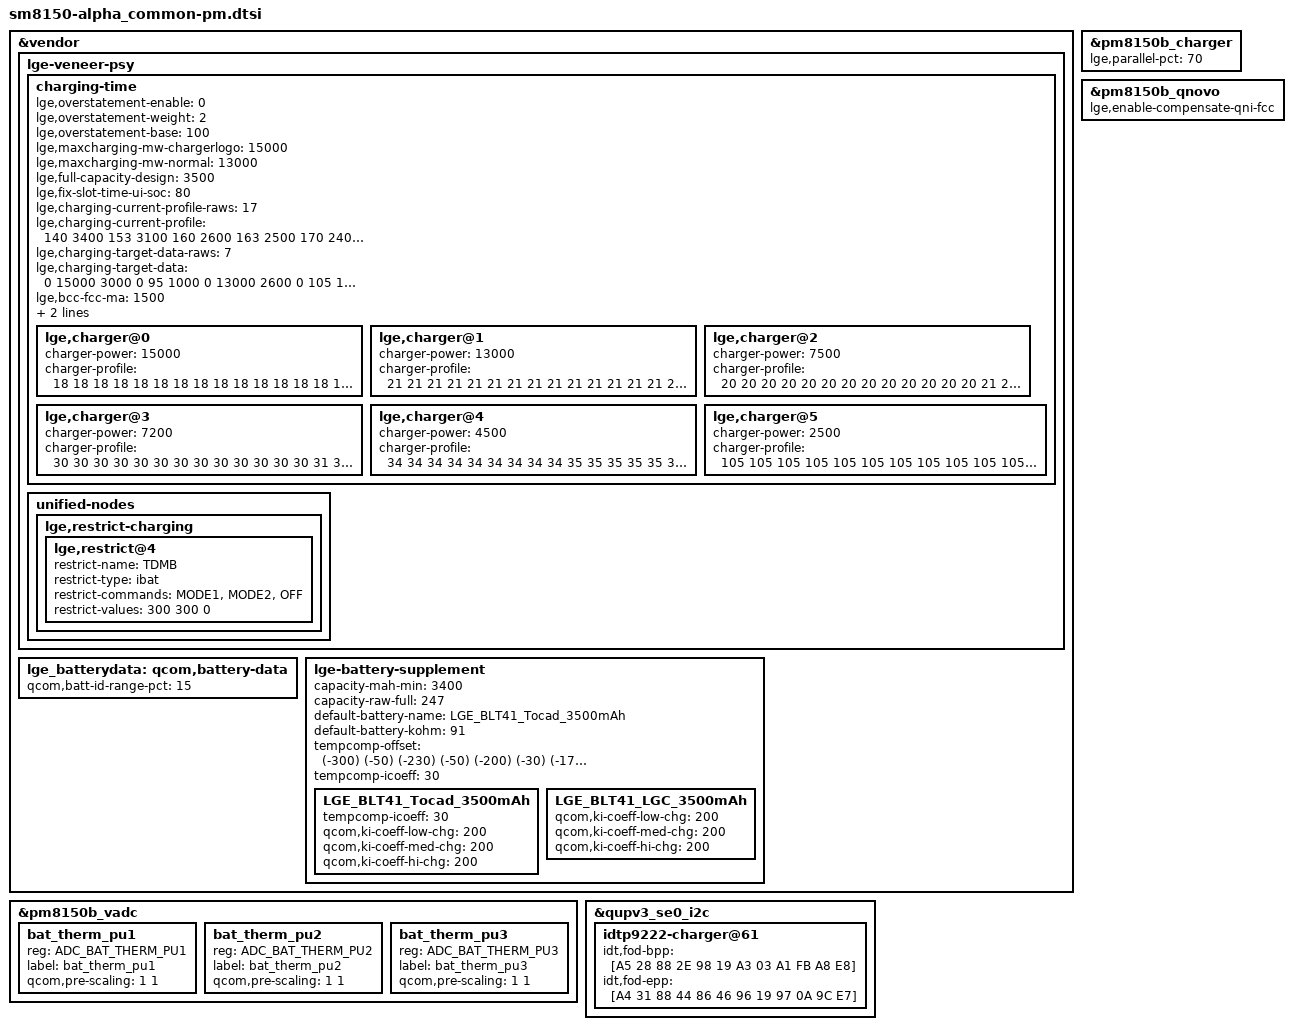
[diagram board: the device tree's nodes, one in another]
/*
 * Copyright (c) 2018, The Linux Foundation. All rights reserved.
 *
 * This program is free software; you can redistribute it and/or modify
 * it under the terms of the GNU General Public License version 2 and
 * only version 2 as published by the Free Software Foundation.
 *
 * This program is distributed in the hope that it will be useful,
 * but WITHOUT ANY WARRANTY; without even the implied warranty of
 * MERCHANTABILITY or FITNESS FOR A PARTICULAR PURPOSE.  See the
 * GNU General Public License for more details.
 */
#include "../../sm8150_common/sm8150_common-pm.dtsi"
&vendor {
	lge-veneer-psy {
		charging-time {
			#address-cells = <1>;
			#size-cells = <0>;
			lge,overstatement-enable = <0>;
			lge,overstatement-weight = <2>;
			lge,overstatement-base = <100>;

			lge,maxcharging-mw-chargerlogo = <15000>;
			lge,maxcharging-mw-normal = <13000>;

			lge,full-capacity-design = <3500>;
			lge,fix-slot-time-ui-soc = <80>;
			lge,charging-current-profile-raws = <17>;
			lge,charging-current-profile = <
				/* format: raw_soc, raw_current(mA) */
				/* CC */
				140  3400
				153  3100
				160  2600
				163  2500
				170  2400
				171  2300
				174  2200
				177  2100
				192  2000
				217  1850
				225  1550
				232  1300
				237  1100
				241  900
				242  800
				245  700
				247  600   /* <- END -> */
			>;

			lge,charging-target-data-raws = <7>;
			lge,charging-target-data = <
			/* format : type, power(mW), current(mA), down(uA), target(min), no_dd_decipct */
			/* 0-type-wired: chargerlogo */   0    15000    3000       0     95    1000
			/* 1-type-wired: power on    */   0    13000    2600       0    105    1000
			/* 2-type-wired: DCP         */   0     7500    1650    1100    150    1000
			/* 3-type-wired: SDP         */   0     2500     500       0    425    1000
			/* 4-type-wireless: EPP      */   1     7200    1068     622    195    1000
			/* 5-type-wireless: BPP      */   1     4500     992     527    215    1000
			/* 6-type-BCC                */   2     7500    1500       0    140    1000
			>;

			// BCC
			lge,bcc-fcc-ma = <1500>;
			bcc-charger-profile = <
				32  32  32  32  32  32  32  32  32  32  32  32  32  32  32  32
				32  32  32  32  32  32  32  32  32  32  32  32  32  32  32  32
				32  32  32  32  32  32  32  32  32  32  32  32  32  32  32  32
				32  32  32  32  32  32  32  32  32  32  32  32  32  32  32  32
				32  32  32  32  32  32  32  32  32  32  32  32  32  32  32  32
				32  32  32  32  32  32  32  32  32  32  32  32  32  32  32  32
				32  32  32  32  32  32  32  32  32  32  32  32  32  32  32  32
				32  32  32  32  32  32  32  32  32  32  32  32  32  32  32  32
				32  32  32  32  32  32  32  32  32  32  32  32  32  32  32  32
				32  32  32  32  32  32  32  32  32  32  32  32  32  32  32  32
				32  32  32  32  32  32  32  32  32  32  32  32  32  32  32  32
				32  32  32  32  32  32  32  32  32  32  32  32  32  32  32  32
				32  32  32  32  32  32  32  32  32  32  32  32  32  32  32  32
				32  32  32  32  32  32  32  32  32  32  40  40  40  40  40  40
				40  40  45  45  45  45  45  45  57  57  57  57  57  57  69  69
				69  73  86  86  86  86  86  86  86  86  86  86  86  86  86  86
			>;

			lge,charger@0 {		//  fast charger: 9V * 1660mA or 5V * 3000mA = 15W
				charger-power = <15000>;
				charger-profile = <
					18  18  18  18  18  18  18  18  18  18  18  18  18  18  18  18
					18  18  18  18  18  18  18  18  18  18  18  18  18  18  18  18
					18  18  18  18  18  18  18  18  18  18  18  18  18  18  18  18
					18  18  18  18  18  18  18  18  18  18  18  18  18  18  18  18
					18  18  18  18  18  18  18  18  18  18  18  18  18  18  18  18
					18  18  18  18  18  18  18  18  18  18  18  18  18  18  18  18
					18  18  18  18  18  18  18  18  18  18  18  18  18  18  18  18
					18  18  18  18  18  18  18  18  18  18  18  18  18  18  18  18
					18  18  18  18  18  18  18  18  18  18  18  18  18  18  18  18
					18  18  18  18  18  18  18  18  18  18  20  20  20  20  20  20
					20  20  20  20  20  20  21  21  21  21  22  22  23  23  24  25
					25  27  27  27  27  27  27  27  27  27  27  27  27  27  27  27
					27  29  29  29  29  29  29  29  29  29  29  29  29  29  29  29
					29  29  29  29  29  29  29  29  29  29  34  34  34  34  34  34
					34  34  41  41  41  41  41  41  48  48  48  48  48  48  59  59
					59  66  76  76  76  76  76  76  76  76  76  76  76  76  76  76
				>;
			};
			lge,charger@1 {		//  power-on fast charger: 2.6A * 4.0V / 80% = 13W
				charger-power = <13000>;
				charger-profile = <
					21  21  21  21  21  21  21  21  21  21  21  21  21  21  21  21
					21  21  21  21  21  21  21  21  21  21  21  21  21  21  21  21
					21  21  21  21  21  21  21  21  21  21  21  21  21  21  21  21
					21  21  21  21  21  21  21  21  21  21  21  21  21  21  21  21
					21  21  21  21  21  21  21  21  21  21  21  21  21  21  21  21
					21  21  21  21  21  21  21  21  21  21  21  21  21  21  21  21
					21  21  21  21  21  21  21  21  21  21  21  21  21  21  21  21
					21  21  21  21  21  21  21  21  21  21  21  21  21  21  21  21
					21  21  21  21  21  21  21  21  21  21  21  21  21  21  21  21
					21  21  21  21  21  21  21  21  21  21  21  21  21  21  21  21
					22  22  22  23  23  23  23  23  23  23  24  25  25  25  25  27
					27  28  28  28  28  28  28  28  28  28  28  28  28  28  28  28
					28  30  30  30  30  30  30  30  30  30  30  30  30  30  30  30
					30  30  30  30  30  30  30  30  30  30  36  36  36  36  36  36
					36  36  43  43  43  43  43  43  51  51  51  51  51  51  62  62
					62  70  80  80  80  80  80  80  80  80  80  80  80  80  80  80
				>;
			};
			lge,charger@2 {		//  dcp charger: 5V * 1500mA = 7.5W
				charger-power = <7500>;
				charger-profile = <
					20  20  20  20  20  20  20  20  20  20  20  20  20  21  21  21
					21  21  21  21  21  21  21  21  21  21  21  22  22  22  22  22
					22  22  22  22  22  22  22  22  23  23  23  23  23  23  23  23
					23  23  23  23  24  24  24  24  24  24  24  24  24  24  24  25
					25  25  25  25  25  25  25  25  25  26  26  26  26  26  26  26
					26  26  26  27  27  27  27  27  27  27  27  28  28  28  28  28
					28  28  28  29  29  29  29  29  29  29  29  30  30  30  30  30
					30  30  31  31  31  31  31  31  31  32  32  32  32  32  32  33
					33  33  33  33  33  34  34  34  34  34  35  35  35  35  35  36
					36  36  36  36  37  37  37  37  37  38  38  38  38  39  39  39
					39  40  40  40  40  41  41  41  41  42  42  42  42  43  43  43
					44  44  44  45  45  45  46  46  46  47  47  47  48  48  48  49
					49  49  50  50  51  51  51  52  52  53  53  54  54  55  55  56
					56  57  57  58  58  59  59  60  60  61  61  62  63  63  64  65
					65  66  67  67  68  69  70  70  71  72  73  74  74  75  76  77
					78  79  80  81  82  83  84  86  86  86  86  86  86  86  86  86
				>;
			};
			lge,charger@3 {		// EPP wireless charger: 9000mV * 800mA = 7.2W
				charger-power = <7200>;
				charger-profile = <
					30  30  30  30  30  30  30  30  30  30  30  30  30  31  31  31
					31  31  31  31  31  31  31  31  31  32  32  32  32  32  32  32
					32  32  32  32  33  33  33  33  33  33  33  33  33  33  34  34
					34  34  34  34  34  34  34  35  35  35  35  35  35  35  35  35
					36  36  36  36  36  36  36  36  36  37  37  37  37  37  37  37
					37  38  38  38  38  38  38  38  39  39  39  39  39  39  39  39
					40  40  40  40  40  40  41  41  41  41  41  41  41  42  42  42
					42  42  42  43  43  43  43  43  43  44  44  44  44  44  44  45
					45  45  45  45  46  46  46  46  46  47  47  47  47  47  48  48
					48  48  48  49  49  49  49  49  50  50  50  50  51  51  51  51
					52  52  52  52  53  53  53  53  54  54  54  54  55  55  55  55
					56  56  56  57  57  57  57  58  58  58  59  59  59  60  60  60
					61  61  61  62  62  62  63  63  63  64  64  65  65  65  66  66
					67  67  67  68  68  69  69  69  70  70  71  71  72  72  73  73
					74  74  75  75  76  76  77  77  78  78  79  80  80  81  81  82
					83  83  84  84  85  86  86  87  87  87  87  87  87  87  87  87
				>;
			};
			lge,charger@4 {		// BPP wireless charger: 6V * 750mA = 4.5W
				charger-power = <4500>;
				charger-profile = <
					34  34  34  34  34  34  34  34  34  35  35  35  35  35  35  35
					35  35  35  35  36  36  36  36  36  36  36  36  36  36  37  37
					37  37  37  37  37  37  37  37  38  38  38  38  38  38  38  38
					38  39  39  39  39  39  39  39  39  39  40  40  40  40  40  40
					40  40  41  41  41  41  41  41  41  41  42  42  42  42  42  42
					42  43  43  43  43  43  43  43  43  44  44  44  44  44  44  44
					45  45  45  45  45  45  46  46  46  46  46  46  47  47  47  47
					47  47  48  48  48  48  48  48  49  49  49  49  49  49  50  50
					50  50  50  51  51  51  51  51  52  52  52  52  52  53  53  53
					53  53  54  54  54  54  55  55  55  55  55  56  56  56  56  57
					57  57  57  58  58  58  58  59  59  59  59  60  60  60  60  61
					61  61  62  62  62  62  63  63  63  64  64  64  65  65  65  66
					66  66  67  67  67  68  68  68  69  69  69  70  70  70  71  71
					72  72  72  73  73  74  74  74  75  75  76  76  76  77  77  78
					78  79  79  80  80  81  81  82  82  83  83  84  84  85  85  86
					86  87  88  88  89  89  90  91  91  91  91  91  91  91  91  91
				>;
			};
			lge,charger@5 {		// SDP: 5000mV * 500mA = 2.5W
				charger-power = <2500>;
				charger-profile = <
					105 105 105 105 105 105 105 105 105 105 105 105 105 105 105 105
					105 105 105 105 105 105 105 105 105 105 105 105 105 105 105 105
					105 105 105 105 105 105 105 105 105 105 105 105 105 105 105 105
					105 105 105 105 105 105 105 105 105 105 105 105 105 105 105 105
					105 105 105 105 105 105 105 105 105 105 105 105 105 105 105 105
					105 105 105 105 105 105 105 105 105 105 105 105 105 105 105 105
					105 105 105 105 105 105 105 105 105 105 105 105 105 105 105 105
					105 105 105 105 105 105 105 105 105 105 105 105 105 105 105 105
					105 105 105 105 105 105 105 105 105 105 105 105 105 105 105 105
					105 105 105 105 105 105 105 105 105 105 105 105 105 105 105 105
					105 105 105 105 105 105 105 105 105 105 105 105 105 105 105 105
					105 105 105 105 105 105 105 105 105 105 105 105 105 105 105 105
					105 105 105 105 105 105 105 105 105 105 105 105 105 105 105 105
					105 105 105 105 105 105 105 105 105 105 105 105 105 105 105 105
					105 105 105 105 105 105 105 105 105 105 105 105 105 105 105 105
					105 105 105 105 105 105 105 105 105 105 105 105 105 105 105 105
				>;
			};
		};
		unified-nodes {
			lge,restrict-charging {
				lge,restrict@4 {
					restrict-name = "TDMB";
					restrict-type = "ibat";
					restrict-commands = "MODE1", "MODE2", "OFF";
					restrict-values = <    300      300      0>;
				};
			};
		};
	};

	lge_batterydata: qcom,battery-data {
		qcom,batt-id-range-pct = <15>;
		#include "../../battery_profile/LGE_BLT41_Tocad_3500mAh.dtsi"
		#include "../../battery_profile/LGE_BLT41_LGC_3500mAh.dtsi"
	};

	lge-battery-supplement {
		capacity-mah-min = <3400>;
		capacity-raw-full = <247>;

		default-battery-name = "LGE_BLT41_Tocad_3500mAh";
		default-battery-kohm = <91>;

		/* format : (temp index) (temp delta) */
		tempcomp-offset = <
			(-300) (-50)
			(-230) (-50)
			(-200) (-30)
			(-170) (-10)
			(-120) (-10)
			( -60) (-20)
			( -10) (-20)
			   40  (-20)
			   80  (-10)
			  130  (-10)
			  170     0
			  220     0
			  260    10
			  310    10
			  370     0
			  420     0
			  480  (-10)
			  520     0
			  570     0
			  620     0
			  660    10
			  700    10
			  730    50
			  750    60
			  800   120
		>;
		tempcomp-icoeff = <30>;
		LGE_BLT41_Tocad_3500mAh {
			tempcomp-icoeff = <30>;
			qcom,ki-coeff-low-chg = <200>;
			qcom,ki-coeff-med-chg = <200>;
			qcom,ki-coeff-hi-chg = <200>;
		};
		LGE_BLT41_LGC_3500mAh {
			qcom,ki-coeff-low-chg = <200>;
			qcom,ki-coeff-med-chg = <200>;
			qcom,ki-coeff-hi-chg = <200>;
		};
	};
};

&pm8150b_charger {
	lge,parallel-pct = <70>;
};

&pm8150b_vadc {
	bat_therm_pu1 {
		reg = <ADC_BAT_THERM_PU1>;
		label = "bat_therm_pu1";
		qcom,pre-scaling = <1 1>;
	};

	bat_therm_pu2 {
		reg = <ADC_BAT_THERM_PU2>;
		label = "bat_therm_pu2";
		qcom,pre-scaling = <1 1>;
	};

	bat_therm_pu3 {
		reg = <ADC_BAT_THERM_PU3>;
		label = "bat_therm_pu3";
		qcom,pre-scaling = <1 1>;
	};
};

&qupv3_se0_i2c {
	idtp9222-charger@61 {
		// FOD parameters
		idt,fod-bpp    = [A5 28 88 2E 98 19 A3 03 A1 FB A8 E8];
		idt,fod-epp    = [A4 31 88 44 86 46 96 19 97 0A 9C E7];
	};
};

&pm8150b_qnovo {
	lge,enable-compensate-qni-fcc;
};
